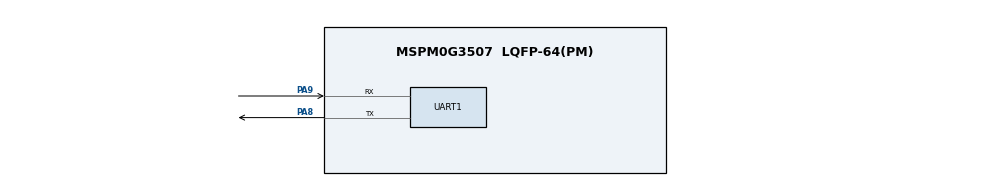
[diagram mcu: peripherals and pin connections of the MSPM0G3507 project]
/**
 * These arguments were used when this file was generated. They will be automatically applied on subsequent loads
 * via the GUI or CLI. Run CLI with '--help' for additional information on how to override these arguments.
 * @cliArgs --device "MSPM0G350X" --part "Default" --package "LQFP-64(PM)" --product "mspm0_sdk@2.10.00.04"
 * @v2CliArgs --device "MSPM0G3507" --package "LQFP-64(PM)" --product "mspm0_sdk@2.10.00.04"
 * @versions {"tool":"1.26.2+4477"}
 */

const SYSCTL = scripting.addModule("/ti/driverlib/SYSCTL");
const UART   = scripting.addModule("/ti/driverlib/UART", {}, false);
const Board  = scripting.addModule("/ti/driverlib/Board", {}, false);
const UART1  = UART.addInstance();

const divider9       = system.clockTree["UDIV"];
divider9.divideValue = 2;

const gate7  = system.clockTree["MFCLKGATE"];
gate7.enable = true;

const multiplier2         = system.clockTree["PLL_QDIV"];
multiplier2.multiplyValue = 4;

const mux4       = system.clockTree["EXHFMUX"];
mux4.inputSelect = "EXHFMUX_XTAL";

const mux8       = system.clockTree["HSCLKMUX"];
mux8.inputSelect = "HSCLKMUX_SYSPLL0";

const mux12       = system.clockTree["SYSPLLMUX"];
mux12.inputSelect = "zSYSPLLMUX_HFCLK";

const pinFunction4        = system.clockTree["HFXT"];
pinFunction4.inputFreq    = 40;
pinFunction4.enable       = true;
pinFunction4.HFXTStartup  = 10;
pinFunction4.HFCLKMonitor = true;

SYSCTL.forceDefaultClkConfig = true;
SYSCTL.clockTreeEn           = true;

UART1.$name                            = "UWB_SMOKE";
UART1.targetBaudRate                   = 921600;
UART1.enableFIFO                       = true;
UART1.rxFifoThreshold                  = "DL_UART_RX_FIFO_LEVEL_ONE_ENTRY";
UART1.enabledInterrupts                = ["RX"];
UART1.peripheral.$assign               = "UART1";
UART1.peripheral.rxPin.$assign         = "PA9";
UART1.peripheral.txPin.$assign         = "PA8";
UART1.txPinConfig.$name                = "ti_driverlib_gpio_GPIOPinGeneric0";
UART1.txPinConfig.direction            = scripting.forceWrite("OUTPUT");
UART1.txPinConfig.hideOutputInversion  = scripting.forceWrite(false);
UART1.txPinConfig.onlyInternalResistor = scripting.forceWrite(false);
UART1.txPinConfig.passedPeripheralType = scripting.forceWrite("Digital");
UART1.rxPinConfig.$name                = "ti_driverlib_gpio_GPIOPinGeneric1";
UART1.rxPinConfig.hideOutputInversion  = scripting.forceWrite(false);
UART1.rxPinConfig.onlyInternalResistor = scripting.forceWrite(false);
UART1.rxPinConfig.passedPeripheralType = scripting.forceWrite("Digital");

pinFunction4.peripheral.$suggestSolution           = "SYSCTL";
pinFunction4.peripheral.hfxInPin.$suggestSolution  = "PA5";
pinFunction4.peripheral.hfxOutPin.$suggestSolution = "PA6";
Board.peripheral.$suggestSolution                  = "DEBUGSS";
Board.peripheral.swclkPin.$suggestSolution         = "PA20";
Board.peripheral.swdioPin.$suggestSolution         = "PA19";
